AUTOSAR XML (schema 4-3-0)
standard types defined: boolean_DataConstr, sint8_DataConstr, sint16_DataConstr, sint32_DataConstr, uint8_DataConstr, uint16_DataConstr, uint32_DataConstr, uint64_DataConstr, boolean, float32, sint8, sint16, sint32, uint8, uint16, uint32, uint64
package /Package_TestSWC1/DataTypes/ImplementationTypes
  4 x impl type:
    st_color1: category=STRUCTURE
      element red: implementation-data-type=float32
      element blue: implementation-data-type=boolean
    st_color2: category=STRUCTURE
      element white: implementation-data-type=boolean
      element black: implementation-data-type=uint8
    st_color1_array_2: category=ARRAY
      element st_color1_array_2: array-size=2, array-size-semantics=FIXED-SIZE, implementation-data-type=st_color1
    uint8_array_32_CS: category=ARRAY
      element uint8_array_32_CS: array-size=32, array-size-semantics=FIXED-SIZE, implementation-data-type=uint8
package /Package_TestSWC1/PortInterfaces
  nv data interface in1  # gqf 1啊 gqf 2的
    nv-datas:
      data in1: type=boolean
  6 x sender receiver interface:
    in2  # in2_xxxx
      data in2: type=boolean
    in3  # gqf 1啊 gqf 2的
      data in3: type=boolean
    in4  # gqf 1啊st gqf 2的st
      data in4: type=st_color1
    in5  # gqf 1啊st gqf 2的st
      data in5: type=st_color1_array_2
    out1  # out1_xxxx
      data out1: type=boolean
    out2  # out2_xxxx out2_xxxx
      data out2: type=uint8
  client server interface PiNVMP_GetAswBlockErrSts: is-service=true  # gqf 3啊 gqf 4的
    operation GetAswBlockErrSts: possible-error=E_NOT_OK
      arg AswBlockId: type=uint32, direction=IN, server-argument-impl-policy=USE-ARGUMENT-TYPE
      arg AswBlockErrSts: type=uint8_array_32_CS, direction=OUT, server-argument-impl-policy=USE-ARGUMENT-TYPE
    error E_NOT_OK: error-code=1
package /Package_TestSWC1/ComponentTypes
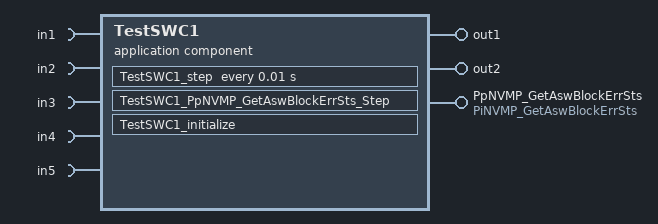
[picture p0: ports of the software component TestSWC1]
  application sw component type TestSWC1
    provide port out1: nonqueued-sender-com-spec{data-element=out1, init-value=0}, provided-interface=out1
    provide port out2: nonqueued-sender-com-spec{data-element=out2, init-value=0}, provided-interface=out2
    provide port PpNVMP_GetAswBlockErrSts: server-com-spec{operation=GetAswBlockErrSts, queue-length=1}, provided-interface=PiNVMP_GetAswBlockErrSts
    5 x require port:
      in1: nv-require-com-spec{init-value=0, variable=in1}, required-interface=in1
      in2: nonqueued-receiver-com-spec{data-element=in2, filter=data-filter-type=ALWAYS, init-value=0}, required-interface=in2
      in3: nonqueued-receiver-com-spec{data-element=in3, enable-update=true, filter=data-filter-type=ALWAYS, init-value=0}, required-interface=in3
      in4: nonqueued-receiver-com-spec{data-element=in4, filter=data-filter-type=ALWAYS, init-value=constant-reference=in4st_color1_Const_1}, required-interface=in4
      in5: nonqueued-receiver-com-spec{data-element=in5, enable-update=true, filter=data-filter-type=ALWAYS, init-value=constant-reference=in5st_color1_Const_2}, required-interface=in5
    behavior TestSWC1_InternalBehavior
      operation invoked event OIT_TestSWC1_PpNVMP_GetAswBlockErrSts_Step_PpNVMP_GetAswBlockErrSts_GetAswBlockErrSts: start-on-event=TestSWC1_PpNVMP_GetAswBlockErrSts_Step, operation=PpNVMP_GetAswBlockErrSts.GetAswBlockErrSts
      timing event Event_Runnable_Step: start-on-event=TestSWC1_step, period=0.01
      init event Event_Runnable_Init: start-on-event=TestSWC1_initialize
      port-api-options:
        enable-take-address=false, indirect-api=false, port=in{1..5}
        enable-take-address=false, indirect-api=false, port=out1
        enable-take-address=false, indirect-api=false, port=out2
        enable-take-address=false, indirect-api=false, port=PpNVMP_GetAswBlockErrSts
      runnable TestSWC1_PpNVMP_GetAswBlockErrSts_Step
      runnable TestSWC1_step
        data-receive-point-by-arguments:
          5 x access:
            REC_in{1..5}_in{1..5}: accessed-variable=in{1..5}.in{1..5}
        data-send-points:
          access SEND_out1_out1: accessed-variable=out1.out1
          access SEND_out2_out2: accessed-variable=out2.out2
      runnable TestSWC1_initialize
  swc implementation TestSWC1_Implementation: behavior=TestSWC1_InternalBehavior
package /Package_TestSWC1/Constants
  constant specification in4st_color1_Const_1: value-spec={short-label=in4st_color1_Const_1, fields=[red:1.3, blue:1]}
  constant specification in5st_color1_Const_2: value-spec=in5st_color1_Const_2:[fields=[red:1.3, blue:1], fields=[red:1.3, blue:1]]
